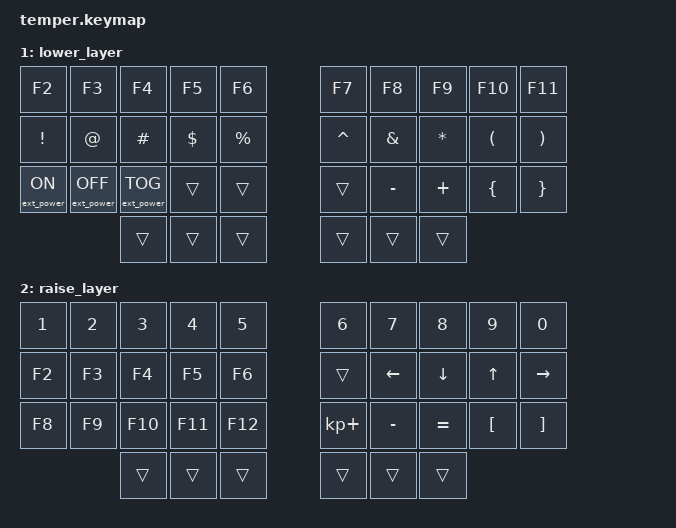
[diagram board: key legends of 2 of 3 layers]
/*
 * Copyright (c) 2020 The ZMK Contributors
 *
 * SPDX-License-Identifier: MIT
 */

#include <behaviors.dtsi>
#include <dt-bindings/zmk/keys.h>
#include <dt-bindings/zmk/bt.h>
#include <dt-bindings/zmk/ext_power.h>

/ {
    keymap {
        compatible = "zmk,keymap";

        default_layer {
// ------------------------------------------------------------------------------------------------------------
// |  Q  |  W  |  E   |  R   |  T   |                   |  Y   |  U    |  I    |  O   |   P   |
// |  A  |  S  |  D   |  F   |  G   |                   |  H   |  J    |  K    |  L   |   ;   |
// |  Z  |  X  |  C   |  V   |  B   |     		|  N   |  M    |  ,    |  .   |   /   |
//                     | GUI  | LOWER|  SPACE |  | ENTER | RAISE| BSPC  |
            bindings = <
&kp Q  &kp W  &kp E    &kp R    &kp T                      &kp Y  &kp U    &kp I     &kp O   &kp P
&kp A  &kp S  &kp D    &kp F    &kp G                      &kp H  &kp J    &kp K     &kp L   &kp SEMI
&kp Z  &kp X  &kp C    &kp V    &kp B  &kp LBKT   &kp RBKT &kp N  &kp M    &kp COMMA &kp DOT &kp FSLH
                        &kp LGUI &mo 1  &kp SPACE  &kp RET  &mo 2  &kp BSPC
            >;

            // sensor-bindings = <&inc_dec_kp C_VOL_UP C_VOL_DN>;
        };

        lower_layer {
// ------------------------------------------------------------------------------------------------------------
// |  F2 |  F3 |  F4  |  F5  |  F6  |                   |  F7  |  F8   |  F9   |  F10 |  F11  |
// |  !  |  @  |  #   |  $   |  %   |                   |  ^   |  &    |  *    |  (   |   )   |
// |     |     |      |      |      |        	        |      |  _    |  +    |  {   |   }   |
//                    |      |      |     |        |    |      |       |       |       
            bindings = <
&kp F2           &kp F3            &kp F4            &kp F5       &kp F6                       &kp F7    &kp F8    &kp F9    &kp F10   &kp F11
&kp EXCL         &kp AT            &kp HASH          &kp DOLLAR   &kp PRCNT                    &kp CARET &kp AMPS  &kp ASTRK &kp LPAR  &kp RPAR
&ext_power EP_ON &ext_power EP_OFF &ext_power EP_TOG &trans       &trans   		       &trans    &kp MINUS &kp PLUS  &kp LBRC  &kp RBRC
                                   &trans            &trans       &trans   		       &trans    &trans    &trans    
            >;

             // sensor-bindings = <&inc_dec_kp C_VOL_UP C_VOL_DN>;
        };

        raise_layer {
// ------------------------------------------------------------------------------------------------------------
// |  1  |  2  |  3   |  4   |  5   |                   |  6   |   7   |   8   |  9   |   0   |
// |  F2 |  F3 |  F4  |  F5  |  F6  |                   |      |   <-  |   v   |  ^   |  ->   |
// |  F8 |  F9 |  F10 |  F11 |  F12 |                   |  +   |   -   |   =   |  [   |   ]   |
//             |      |      |      |                   |      |       |       |
            bindings = <
&kp N1 &kp N2 &kp N3  &kp N4  &kp N5                       &kp N6      &kp N7    &kp N8    &kp N9   &kp N0    
&kp F2 &kp F3 &kp F4  &kp F5  &kp F6                       &trans      &kp LEFT  &kp DOWN  &kp UP   &kp RIGHT 
&kp F8 &kp F9 &kp F10 &kp F11 &kp F12   		   &kp KP_PLUS &kp MINUS &kp EQUAL &kp LBKT &kp RBKT  
              &trans  &trans  &trans        		   &trans      &trans    &trans
            >;

            // sensor-bindings = <&inc_dec_kp C_VOL_UP C_VOL_DN>;
        };
    };
};
